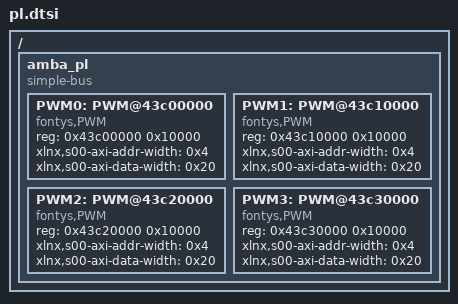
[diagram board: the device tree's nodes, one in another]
/*
 * CAUTION: This file is automatically generated by Xilinx.
 * Version:  
 * Today is: Fri Apr  8 11:16:21 2016
*/


/ {
	amba_pl: amba_pl {
		#address-cells = <1>;
		#size-cells = <1>;
		compatible = "simple-bus";
		ranges ;
		PWM0: PWM@43c00000 {
			compatible = "fontys,PWM";
			reg = <0x43c00000 0x10000>;
			xlnx,s00-axi-addr-width = <0x4>;
			xlnx,s00-axi-data-width = <0x20>;
		};
		PWM1: PWM@43c10000 {
			compatible = "fontys,PWM";
			reg = <0x43c10000 0x10000>;
			xlnx,s00-axi-addr-width = <0x4>;
			xlnx,s00-axi-data-width = <0x20>;
		};
		PWM2: PWM@43c20000 {
			compatible = "fontys,PWM";
			reg = <0x43c20000 0x10000>;
			xlnx,s00-axi-addr-width = <0x4>;
			xlnx,s00-axi-data-width = <0x20>;
		};
		PWM3: PWM@43c30000 {
			compatible = "fontys,PWM";
			reg = <0x43c30000 0x10000>;
			xlnx,s00-axi-addr-width = <0x4>;
			xlnx,s00-axi-data-width = <0x20>;
		};
	};
};
